# MAX32600 register map
File version: 1.0
Registers are 32-bit, read-write, reset 0x0 unless marked. A register's access mark holds for its fields unless they carry their own. Offsets are from the block's base; [hi:lo] are bit positions; {n}, {i} and the like mark numbered series.

## PWRMAN — System Power Manager
Base 0x40090800
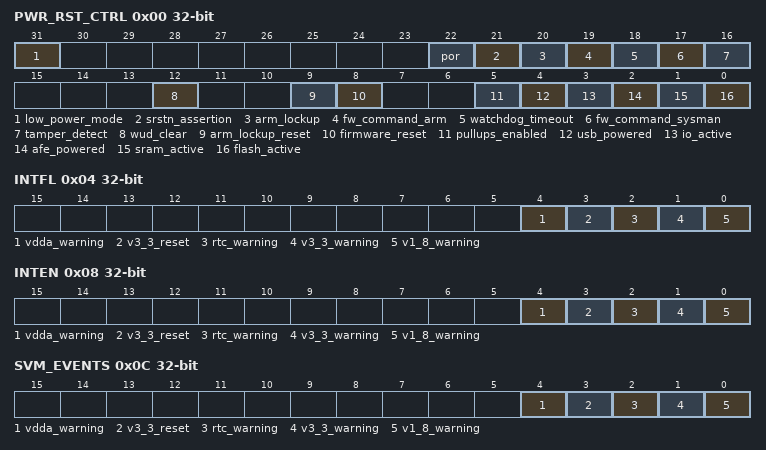
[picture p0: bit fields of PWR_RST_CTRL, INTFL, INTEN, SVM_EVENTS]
0x00 PWR_RST_CTRL — Power Reset Control and Status
  [31] low_power_mode — Power Manager Dynamic Clock Gating Enable
  [22] por ro — Reset Caused By - Power On Reset (POR)
  [21] srstn_assertion ro — Reset Caused By - External System Reset
  [20] arm_lockup ro — Reset Caused By - ARM Lockup
  [19] fw_command_arm ro — Reset Caused By - Firmware Commanded Reset (ARM Core)
  [18] watchdog_timeout ro — Reset Caused By - Watchdog Reset
  [17] fw_command_sysman ro — Reset Caused By - Firmware Commanded Reset (SysMan)
  [16] tamper_detect ro — Reset Caused By - Tamper Detect
  [12] wud_clear — I/O WUD Clear
  [9] arm_lockup_reset
  [8] firmware_reset — Firmware Initiated Reset
  [5] pullups_enabled — Static Pullups Enabled
  [4] usb_powered
  [3] io_active
  [2] afe_powered
  [1] sram_active — SRAM Active (Not Used)
  [0] flash_active — Flash Active (Not Used)
0x04 INTFL — Interrupt Flags
  [4] vdda_warning write-1-clears — VddA Warning Monitor Int Flag
  [3] v3_3_reset write-1-clears — 3.3V Reset Monitor Int Flag
  [2] rtc_warning write-1-clears — RTC Warning Monitor Int Flag
  [1] v3_3_warning write-1-clears — 3.3V Warning Monitor Int Flag
  [0] v1_8_warning write-1-clears — 1.8V Warning Monitor Int Flag
0x08 INTEN — Interrupt Enable/Disable Controls
  [4] vdda_warning — VddA Warning Monitor Int Enable
  [3] v3_3_reset — 3.3V Reset Monitor Int Enable
  [2] rtc_warning — RTC Warning Monitor Int Enable
  [1] v3_3_warning — 3.3V Warning Monitor Int Enable
  [0] v1_8_warning — 1.8V Warning Monitor Int Enable
0x0C SVM_EVENTS — SVM Event Status Flags (read-only)
  [4] vdda_warning ro — VddA Warning Monitor Event Input
  [3] v3_3_reset ro — 3.3V Reset Monitor Event Input
  [2] rtc_warning ro — RTC Warning Monitor Event Input
  [1] v3_3_warning ro — 3.3V Warning Monitor Event Input
  [0] v1_8_warning ro — 1.8V Warning Monitor Event Input
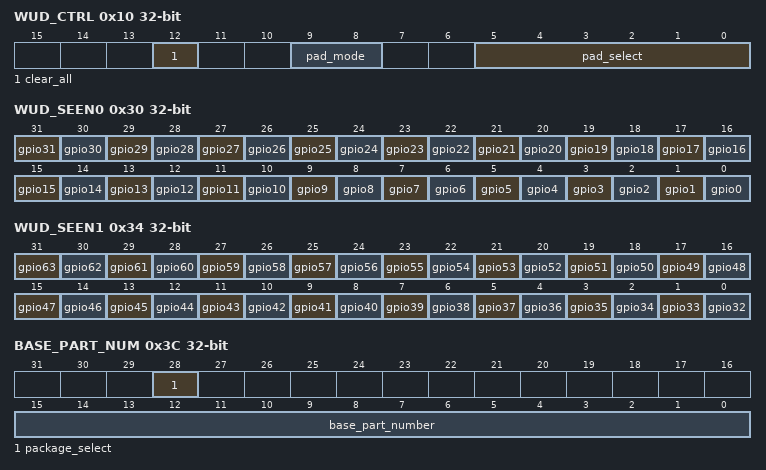
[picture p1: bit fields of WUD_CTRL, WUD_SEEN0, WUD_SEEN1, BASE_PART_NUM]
0x10 WUD_CTRL — Wake-Up Detect Control
  [12] clear_all — Clear All WUD Pad States
  [9:8] pad_mode — Wake-Up Pad Signal Mode
  [5:0] pad_select — Wake-Up Pad Select
0x14 WUD_PULSE0 — WUD Pulse To Mode Bit 0
0x18 WUD_PULSE1 — WUD Pulse To Mode Bit 1
0x30 WUD_SEEN0 — Wake-up Detect Status for P0/P1/P2/P3
  [31] gpio31 ro — Wake-Up Detect Status for P3.7
  [30] gpio30 ro — Wake-Up Detect Status for P3.6
  [29] gpio29 ro — Wake-Up Detect Status for P3.5
  [28] gpio28 ro — Wake-Up Detect Status for P3.4
  [27] gpio27 ro — Wake-Up Detect Status for P3.3
  [26] gpio26 ro — Wake-Up Detect Status for P3.2
  [25] gpio25 ro — Wake-Up Detect Status for P3.1
  [24] gpio24 ro — Wake-Up Detect Status for P3.0
  [23] gpio23 ro — Wake-Up Detect Status for P2.7
  [22] gpio22 ro — Wake-Up Detect Status for P2.6
  [21] gpio21 ro — Wake-Up Detect Status for P2.5
  [20] gpio20 ro — Wake-Up Detect Status for P2.4
  [19] gpio19 ro — Wake-Up Detect Status for P2.3
  [18] gpio18 ro — Wake-Up Detect Status for P2.2
  [17] gpio17 ro — Wake-Up Detect Status for P2.1
  [16] gpio16 ro — Wake-Up Detect Status for P2.0
  [15] gpio15 ro — Wake-Up Detect Status for P1.7
  [14] gpio14 ro — Wake-Up Detect Status for P1.6
  [13] gpio13 ro — Wake-Up Detect Status for P1.5
  [12] gpio12 ro — Wake-Up Detect Status for P1.4
  [11] gpio11 ro — Wake-Up Detect Status for P1.3
  [10] gpio10 ro — Wake-Up Detect Status for P1.2
  [9] gpio9 ro — Wake-Up Detect Status for P1.1
  [8] gpio8 ro — Wake-Up Detect Status for P1.0
  [7] gpio7 ro — Wake-Up Detect Status for P0.7
  [6] gpio6 ro — Wake-Up Detect Status for P0.6
  [5] gpio5 ro — Wake-Up Detect Status for P0.5
  [4] gpio4 ro — Wake-Up Detect Status for P0.4
  [3] gpio3 ro — Wake-Up Detect Status for P0.3
  [2] gpio2 ro — Wake-Up Detect Status for P0.2
  [1] gpio1 ro — Wake-Up Detect Status for P0.1
  [0] gpio0 ro — Wake-Up Detect Status for P0.0
0x34 WUD_SEEN1 — Wake-up Detect Status for P4/P5/P6/P7
  [31] gpio63 ro — Wake-Up Detect Status for P7.7
  [30] gpio62 ro — Wake-Up Detect Status for P7.6
  [29] gpio61 ro — Wake-Up Detect Status for P7.5
  [28] gpio60 ro — Wake-Up Detect Status for P7.4
  [27] gpio59 ro — Wake-Up Detect Status for P7.3
  [26] gpio58 ro — Wake-Up Detect Status for P7.2
  [25] gpio57 ro — Wake-Up Detect Status for P7.1
  [24] gpio56 ro — Wake-Up Detect Status for P7.0
  [23] gpio55 ro — Wake-Up Detect Status for P6.7
  [22] gpio54 ro — Wake-Up Detect Status for P6.6
  [21] gpio53 ro — Wake-Up Detect Status for P6.5
  [20] gpio52 ro — Wake-Up Detect Status for P6.4
  [19] gpio51 ro — Wake-Up Detect Status for P6.3
  [18] gpio50 ro — Wake-Up Detect Status for P6.2
  [17] gpio49 ro — Wake-Up Detect Status for P6.1
  [16] gpio48 ro — Wake-Up Detect Status for P6.0
  [15] gpio47 ro — Wake-Up Detect Status for P5.7
  [14] gpio46 ro — Wake-Up Detect Status for P5.6
  [13] gpio45 ro — Wake-Up Detect Status for P5.5
  [12] gpio44 ro — Wake-Up Detect Status for P5.4
  [11] gpio43 ro — Wake-Up Detect Status for P5.3
  [10] gpio42 ro — Wake-Up Detect Status for P5.2
  [9] gpio41 ro — Wake-Up Detect Status for P5.1
  [8] gpio40 ro — Wake-Up Detect Status for P5.0
  [7] gpio39 ro — Wake-Up Detect Status for P4.7
  [6] gpio38 ro — Wake-Up Detect Status for P4.6
  [5] gpio37 ro — Wake-Up Detect Status for P4.5
  [4] gpio36 ro — Wake-Up Detect Status for P4.4
  [3] gpio35 ro — Wake-Up Detect Status for P4.3
  [2] gpio34 ro — Wake-Up Detect Status for P4.2
  [1] gpio33 ro — Wake-Up Detect Status for P4.1
  [0] gpio32 ro — Wake-Up Detect Status for P4.0
0x38 DIE_TYPE — Die Type ID Register
0x3C BASE_PART_NUM — Base Part Number
  [28] package_select ro, [15:0] base_part_number ro
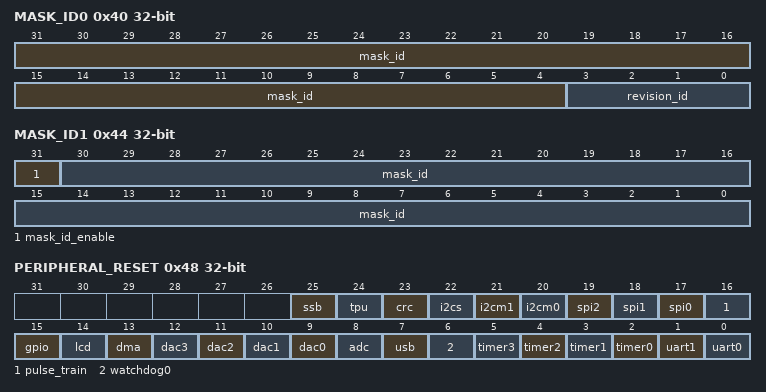
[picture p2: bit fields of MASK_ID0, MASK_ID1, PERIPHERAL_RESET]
0x40 MASK_ID0 — Mask ID Register 0
  [31:4] mask_id ro — Mask ID[27:0]
  [3:0] revision_id ro
0x44 MASK_ID1 — Mask ID Register 1
  [31] mask_id_enable — Enable Mask ID
  [30:0] mask_id ro — Mask ID[58:28]
0x48 PERIPHERAL_RESET — Peripheral Reset Control Register
  [25] ssb — Reset RTC SSB
  [24] tpu — Reset TPU
  [23] crc — Reset CRC Engine
  [22] i2cs — Reset I2C Slave
  [21] i2cm1 — Reset I2C Master 1
  [20] i2cm0 — Reset I2C Master 0
  [19] spi2 — Reset SPI 2
  [18] spi1 — Reset SPI 1
  [17] spi0 — Reset SPI 0
  [16] pulse_train — Reset All Pulse Trains
  [15] gpio — Reset GPIO Module
  [14] lcd — Reset LCD
  [13] dma — Reset DMA/PMU
  [12] dac3 — Reset 8-Bit DAC 1
  [11] dac2 — Reset 8-Bit DAC 0
  [10] dac1 — Reset 12-Bit DAC 1
  [9] dac0 — Reset 12-Bit DAC 0
  [8] adc — Reset ADC
  [7] usb — Reset USB
  [6] watchdog0 — Reset Watchdog Timer 0
  [n+2] timer{n} (n=0..3) — Reset Timer{n}
  [1] uart1 — Reset UART1
  [0] uart0 — Reset UART0
